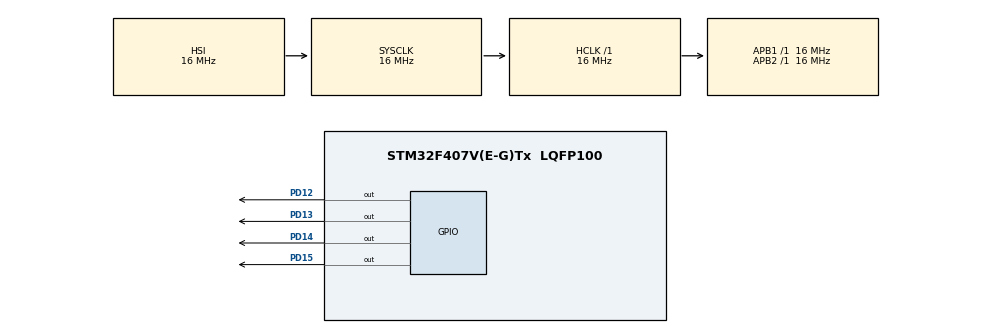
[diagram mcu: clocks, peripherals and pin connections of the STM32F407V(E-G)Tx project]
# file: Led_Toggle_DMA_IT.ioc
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Dma.MEMTOMEM.0.Direction=DMA_MEMORY_TO_MEMORY
Dma.MEMTOMEM.0.FIFOMode=DMA_FIFOMODE_ENABLE
Dma.MEMTOMEM.0.FIFOThreshold=DMA_FIFO_THRESHOLD_FULL
Dma.MEMTOMEM.0.Instance=DMA2_Stream0
Dma.MEMTOMEM.0.MemBurst=DMA_MBURST_SINGLE
Dma.MEMTOMEM.0.MemDataAlignment=DMA_MDATAALIGN_WORD
Dma.MEMTOMEM.0.MemInc=DMA_MINC_ENABLE
Dma.MEMTOMEM.0.Mode=DMA_NORMAL
Dma.MEMTOMEM.0.PeriphBurst=DMA_PBURST_SINGLE
Dma.MEMTOMEM.0.PeriphDataAlignment=DMA_PDATAALIGN_WORD
Dma.MEMTOMEM.0.PeriphInc=DMA_PINC_ENABLE
Dma.MEMTOMEM.0.Priority=DMA_PRIORITY_LOW
Dma.Request0=MEMTOMEM
Mcu.Family=STM32F4
Mcu.Name=STM32F407V(E-G)Tx
Mcu.Package=LQFP100
NVIC.DMA2_Stream0_IRQn=true\:0\:0\:false\:false\:true\:true\:true\:true
NVIC.PriorityGroup=NVIC_PRIORITYGROUP_4
PD12.Signal=GPIO_Output
PD13.Signal=GPIO_Output
PD14.Signal=GPIO_Output
PD15.Signal=GPIO_Output
ProjectManager.HeapSize=0x200
ProjectManager.StackSize=0x400
ProjectManager.TargetToolchain=STM32CubeIDE
RCC.AHBFreq_Value=16000000
RCC.APB1Freq_Value=16000000
RCC.APB2Freq_Value=16000000
RCC.CortexFreq_Value=16000000
RCC.HSE_VALUE=25000000
RCC.HSI_VALUE=16000000
RCC.LSE_VALUE=32768
RCC.SYSCLKFreq_VALUE=16000000
RCC.VCOOutputFreq_Value=192000000
board=custom

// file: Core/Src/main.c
/* USER CODE BEGIN Header */
/**
  ******************************************************************************
  * @file           : main.c
  * @brief          : Main program body
  ******************************************************************************
  * @attention
  *
  * Copyright (c) 2025 STMicroelectronics.
  * All rights reserved.
  *
  * This software is licensed under terms that can be found in the LICENSE file
  * in the root directory of this software component.
  * If no LICENSE file comes with this software, it is provided AS-IS.
  *
  ******************************************************************************
  */
/* USER CODE END Header */
#include "main.h"

DMA_HandleTypeDef hdma_memtomem_dma2_stream0;
/* USER CODE BEGIN PV */
uint32_t led_data[] = {GPIO_PIN_12, GPIO_PIN_12 << 16, GPIO_PIN_13, GPIO_PIN_13 << 16, GPIO_PIN_14, GPIO_PIN_14 << 16, GPIO_PIN_15, GPIO_PIN_15 << 16 };
int len = sizeof(led_data)/ sizeof(uint32_t);
uint32_t current_ticks = 0;
/* USER CODE END PV */

void SystemClock_Config(void);
static void MX_DMA_Init(void);
static void MX_GPIO_Init(void);
/* USER CODE BEGIN PFP */
void My_Dma_Tc_Cb (DMA_HandleTypeDef *pHandle);
/* USER CODE END PFP */

int main(void)
{

  /* MCU Configuration--------------------------------------------------------*/

  /* Reset of all peripherals, Initializes the Flash interface and the Systick. */
  HAL_Init();

  /* Configure the system clock */
  SystemClock_Config();

  /* Initialize all configured peripherals */
  MX_DMA_Init();
  MX_GPIO_Init();
  /* USER CODE BEGIN 2 */
  HAL_DMA_RegisterCallback(&hdma_memtomem_dma2_stream0, HAL_DMA_XFER_CPLT_CB_ID, &My_Dma_Tc_Cb);

  /* USER CODE END 2 */

  /* Infinite loop */
  while (1)
  {
	for(int i=0; i< len; i++){
		HAL_DMA_Start_IT(&hdma_memtomem_dma2_stream0, (uint32_t)&led_data[i], (uint32_t)&GPIOD->ODR, 1);

		current_ticks = HAL_GetTick();
		while( (current_ticks + 1000) >= HAL_GetTick() );

		HAL_DMA_Start_IT(&hdma_memtomem_dma2_stream0, (uint32_t)&led_data[i], (uint32_t)&GPIOD->ODR, 1);

		current_ticks = HAL_GetTick();
		while( (current_ticks + 1000) >= HAL_GetTick() );

	}

  }
}

void SystemClock_Config(void)
{
  RCC_OscInitTypeDef RCC_OscInitStruct = {0};
  RCC_ClkInitTypeDef RCC_ClkInitStruct = {0};

  /** Configure the main internal regulator output voltage
  */
  __HAL_RCC_PWR_CLK_ENABLE();
  __HAL_PWR_VOLTAGESCALING_CONFIG(PWR_REGULATOR_VOLTAGE_SCALE1);

  /** Initializes the RCC Oscillators according to the specified parameters
  * in the RCC_OscInitTypeDef structure.
  */
  RCC_OscInitStruct.OscillatorType = RCC_OSCILLATORTYPE_HSI;
  RCC_OscInitStruct.HSIState = RCC_HSI_ON;
  RCC_OscInitStruct.HSICalibrationValue = RCC_HSICALIBRATION_DEFAULT;
  RCC_OscInitStruct.PLL.PLLState = RCC_PLL_NONE;
  if (HAL_RCC_OscConfig(&RCC_OscInitStruct) != HAL_OK)
  {
    Error_Handler();
  }

  /** Initializes the CPU, AHB and APB buses clocks
  */
  RCC_ClkInitStruct.ClockType = RCC_CLOCKTYPE_HCLK|RCC_CLOCKTYPE_SYSCLK
                              |RCC_CLOCKTYPE_PCLK1|RCC_CLOCKTYPE_PCLK2;
  RCC_ClkInitStruct.SYSCLKSource = RCC_SYSCLKSOURCE_HSI;
  RCC_ClkInitStruct.AHBCLKDivider = RCC_SYSCLK_DIV1;
  RCC_ClkInitStruct.APB1CLKDivider = RCC_HCLK_DIV1;
  RCC_ClkInitStruct.APB2CLKDivider = RCC_HCLK_DIV1;

  if (HAL_RCC_ClockConfig(&RCC_ClkInitStruct, FLASH_LATENCY_0) != HAL_OK)
  {
    Error_Handler();
  }
}

static void MX_DMA_Init(void)
{

  /* DMA controller clock enable */
  __HAL_RCC_DMA2_CLK_ENABLE();

  /* Configure DMA request hdma_memtomem_dma2_stream0 on DMA2_Stream0 */
  hdma_memtomem_dma2_stream0.Instance = DMA2_Stream0;
  hdma_memtomem_dma2_stream0.Init.Channel = DMA_CHANNEL_0;
  hdma_memtomem_dma2_stream0.Init.Direction = DMA_MEMORY_TO_MEMORY;
  hdma_memtomem_dma2_stream0.Init.PeriphInc = DMA_PINC_ENABLE;
  hdma_memtomem_dma2_stream0.Init.MemInc = DMA_MINC_ENABLE;
  hdma_memtomem_dma2_stream0.Init.PeriphDataAlignment = DMA_PDATAALIGN_WORD;
  hdma_memtomem_dma2_stream0.Init.MemDataAlignment = DMA_MDATAALIGN_WORD;
  hdma_memtomem_dma2_stream0.Init.Mode = DMA_NORMAL;
  hdma_memtomem_dma2_stream0.Init.Priority = DMA_PRIORITY_LOW;
  hdma_memtomem_dma2_stream0.Init.FIFOMode = DMA_FIFOMODE_ENABLE;
  hdma_memtomem_dma2_stream0.Init.FIFOThreshold = DMA_FIFO_THRESHOLD_FULL;
  hdma_memtomem_dma2_stream0.Init.MemBurst = DMA_MBURST_SINGLE;
  hdma_memtomem_dma2_stream0.Init.PeriphBurst = DMA_PBURST_SINGLE;
  if (HAL_DMA_Init(&hdma_memtomem_dma2_stream0) != HAL_OK)
  {
    Error_Handler( );
  }

  /* DMA interrupt init */
  /* DMA2_Stream0_IRQn interrupt configuration */
  HAL_NVIC_SetPriority(DMA2_Stream0_IRQn, 0, 0);
  HAL_NVIC_EnableIRQ(DMA2_Stream0_IRQn);

}

static void MX_GPIO_Init(void)
{
  GPIO_InitTypeDef GPIO_InitStruct = {0};

  /* GPIO Ports Clock Enable */
  __HAL_RCC_GPIOD_CLK_ENABLE();

  /*Configure GPIO pin Output Level */
  HAL_GPIO_WritePin(GPIOD, GPIO_PIN_12|GPIO_PIN_13|GPIO_PIN_14|GPIO_PIN_15, GPIO_PIN_RESET);

  /*Configure GPIO pins : PD12 PD13 PD14 PD15 */
  GPIO_InitStruct.Pin = GPIO_PIN_12|GPIO_PIN_13|GPIO_PIN_14|GPIO_PIN_15;
  GPIO_InitStruct.Mode = GPIO_MODE_OUTPUT_PP;
  GPIO_InitStruct.Pull = GPIO_NOPULL;
  GPIO_InitStruct.Speed = GPIO_SPEED_FREQ_LOW;
  HAL_GPIO_Init(GPIOD, &GPIO_InitStruct);

}

/* USER CODE BEGIN 4 */
void My_Dma_Tc_Cb (DMA_HandleTypeDef *pHandle){

}

/* USER CODE END 4 */

void Error_Handler(void)
{
  __disable_irq();
  while (1)
  {
  }
}
